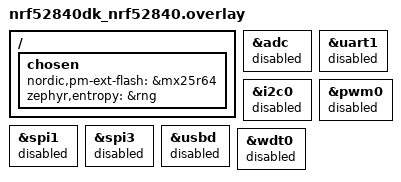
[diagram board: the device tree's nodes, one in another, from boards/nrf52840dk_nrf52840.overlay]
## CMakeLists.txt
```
#
# Copyright (c) 2021 Nordic Semiconductor ASA
#
# SPDX-License-Identifier: LicenseRef-Nordic-5-Clause
#

cmake_minimum_required(VERSION 3.20.0)

find_package(Zephyr HINTS $ENV{ZEPHYR_BASE})

project(matter-template)

# Enable GNU STD support.
include(${ZEPHYR_CONNECTEDHOMEIP_MODULE_DIR}/config/nrfconnect/app/enable-gnu-std.cmake)

# NORDIC SDK APP START

# Include all source files that are located in the Matter common directory.
include(${ZEPHYR_NRF_MODULE_DIR}/samples/matter/common/cmake/source_common.cmake)

# Include Data Model utils
include(${ZEPHYR_NRF_MODULE_DIR}/samples/matter/common/cmake/data_model.cmake)

include(${ZEPHYR_NRF_MODULE_DIR}/samples/matter/common/cmake/zap_helpers.cmake)
ncs_get_zap_parent_dir(ZAP_PARENT_DIR)

target_include_directories(app PRIVATE
    src
    ${ZAP_PARENT_DIR}
)

target_sources(app PRIVATE
    src/app_task.cpp
    src/main.cpp
)

ncs_configure_data_model()
# NORDIC SDK APP END
```

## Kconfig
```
#
# Copyright (c) 2022 Nordic Semiconductor
#
# SPDX-License-Identifier: LicenseRef-Nordic-5-Clause
#
mainmenu "Matter nRF Connect Template Example Application"

# Sample configuration used for Thread networking
if OPENTHREAD

choice OPENTHREAD_NORDIC_LIBRARY_CONFIGURATION
	default OPENTHREAD_NORDIC_LIBRARY_MTD
endchoice

choice OPENTHREAD_DEVICE_TYPE
	default OPENTHREAD_MTD
endchoice

# SED with 0 dBm Thread TX output power for nRF54L15 tag
if BOARD_NRF54L15TAG

config CHIP_ENABLE_ICD_SUPPORT
	default y

config OPENTHREAD_DEFAULT_TX_POWER
	default 0

endif

endif # OPENTHREAD

config CHIP_WIFI
	default y if SHIELD_NRF7002EB2

source "$(ZEPHYR_CONNECTEDHOMEIP_MODULE_DIR)/config/nrfconnect/chip-module/Kconfig.features"
source "$(ZEPHYR_CONNECTEDHOMEIP_MODULE_DIR)/config/nrfconnect/chip-module/Kconfig.defaults"
source "$(ZEPHYR_NRF_MODULE_DIR)/samples/matter/common/src/Kconfig"
source "Kconfig.zephyr"
```

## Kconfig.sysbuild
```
#
# Copyright (c) 2023 Nordic Semiconductor ASA
#
# SPDX-License-Identifier: LicenseRef-Nordic-5-Clause
#

#### Radio core selection
config NRF_DEFAULT_IPC_RADIO
	default y

# Enable IEEE802.15.4 serialization to network core
# This config automatically pulls in the `overlay-802154.conf` in the ipc_radio image
config NETCORE_IPC_RADIO_IEEE802154
	default y if SOC_SERIES_NRF53 && !WIFI_NRF70

# Enable Bluetooth serialization to network core
# This config automatically pulls in the `overlay-bt_hci_ipc.conf` in the ipc_radio image
config NETCORE_IPC_RADIO_BT_HCI_IPC
	default y if SOC_SERIES_NRF53

#### Bootloader
choice BOOTLOADER
	default BOOTLOADER_MCUBOOT if !BOARD_NRF21540DK
endchoice

# The nRF54LC10 DK keeps MCUboot but uses a single application slot:
# it has no external flash and its RRAM cannot hold two Matter-sized slots.
# DFU can be added by introducing external flash.
config MATTER_OTA
	default n if BOARD_NRF54LC10DK

if BOOTLOADER_MCUBOOT

#### DFU multi-image support
config DFU_MULTI_IMAGE_PACKAGE_BUILD
	default y

config DFU_MULTI_IMAGE_PACKAGE_APP
	default y

#### DFU network core configuration
if SOC_SERIES_NRF53

choice MCUBOOT_MODE
	default MCUBOOT_MODE_OVERWRITE_ONLY
endchoice

choice BOOT_SIGNATURE_TYPE
	default BOOT_SIGNATURE_TYPE_RSA
endchoice

config SECURE_BOOT_NETCORE
	default y

config NETCORE_APP_UPDATE
	default y

config MCUBOOT_NRF53_MULTI_IMAGE_UPDATE
	default y if NETCORE_APP_UPDATE

config DFU_MULTI_IMAGE_PACKAGE_NET
	default y

endif # SOC_SERIES_NRF53

endif # BOOTLOADER_MCUBOOT

#### Enable generating factory data
config MATTER_FACTORY_DATA_GENERATE
	default y if !BOARD_NRF21540DK

# Internal flash only for nRF54L15 tag with compression
if BOARD_NRF54L15TAG

choice MCUBOOT_MODE
	default MCUBOOT_MODE_OVERWRITE_ONLY
endchoice

config MCUBOOT_COMPRESSED_IMAGE_SUPPORT
	default y

endif

# Disable Secondary slot for nRF54LC10 DK since it lacks memory to support it.
if BOARD_NRF54LC10DK

choice MCUBOOT_MODE
	default MCUBOOT_MODE_SINGLE_APP
endchoice

endif

# Partition Manager backwards compatibility
if PARTITION_MANAGER

if SOC_NRF54L10

config PM_MCUBOOT_PAD
	default 0x1000

endif # SOC_NRF54L10

if BOARD_NRF54L15TAG

config PM_OVERRIDE_EXTERNAL_DRIVER_CHECK
	default y

config PM_EXTERNAL_FLASH_MCUBOOT_SECONDARY
	default y

endif # BOARD_NRF54L15TAG

if BOARD_NRF54L15DK || BOARD_NRF54LM20DK

# Disable checking the external drivers for nRF54L15 and nRF54LM20 DKs.
config PM_OVERRIDE_EXTERNAL_DRIVER_CHECK
	default y

endif # BOARD_NRF54L15DK || BOARD_NRF54LM20DK

if BOOTLOADER_MCUBOOT

config PM_EXTERNAL_FLASH_MCUBOOT_SECONDARY
	default y

endif # BOOTLOADER_MCUBOOT

endif # PARTITION_MANAGER

source "share/sysbuild/Kconfig"
```

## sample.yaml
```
sample:
  description: Matter Template sample
  name: Matter Template
common:
  tags:
    - sysbuild
    - ci_samples_matter
tests:
  sample.matter.template.debug:
    sysbuild: true
    build_only: true
    extra_args:
      - CONFIG_NCS_SAMPLE_MATTER_OPERATIONAL_KEYS_MIGRATION_TO_ITS=y
    integration_platforms:
      - nrf52840dk/nrf52840
      - nrf5340dk/nrf5340/cpuapp
      - nrf54l15dk/nrf54l15/cpuapp
      - nrf54l15dk/nrf54l10/cpuapp
      - nrf54l15tag/nrf54l15/cpuapp
      - nrf54lm20dk/nrf54lm20b/cpuapp
      - nrf54lm20dk/nrf54lm20a/cpuapp
      - nrf54lc10dk/nrf54lc10a/cpuapp
    platform_allow:
      - nrf52840dk/nrf52840
      - nrf5340dk/nrf5340/cpuapp
      - nrf54l15dk/nrf54l15/cpuapp
      - nrf54l15dk/nrf54l10/cpuapp
      - nrf54l15tag/nrf54l15/cpuapp
      - nrf54lm20dk/nrf54lm20b/cpuapp
      - nrf54lm20dk/nrf54lm20a/cpuapp
      - nrf54lc10dk/nrf54lc10a/cpuapp
  sample.matter.template.nrf7002eb2.debug:
    sysbuild: true
    build_only: true
    extra_args:
      - template_SHIELD=nrf7002eb2
      - SB_CONFIG_WIFI_NRF70=y
    integration_platforms:
      - nrf54lm20dk/nrf54lm20b/cpuapp
      - nrf54lm20dk/nrf54lm20a/cpuapp
    platform_allow:
      - nrf54lm20dk/nrf54lm20b/cpuapp
      - nrf54lm20dk/nrf54lm20a/cpuapp
  sample.matter.template.release:
    sysbuild: true
    build_only: true
    extra_args:
      - FILE_SUFFIX=release
      - CONFIG_NCS_SAMPLE_MATTER_OPERATIONAL_KEYS_MIGRATION_TO_ITS=y
    integration_platforms:
      - nrf52840dk/nrf52840
      - nrf5340dk/nrf5340/cpuapp
      - nrf54l15dk/nrf54l15/cpuapp
      - nrf54l15dk/nrf54l10/cpuapp
      - nrf54l15tag/nrf54l15/cpuapp
      - nrf54lm20dk/nrf54lm20b/cpuapp
      - nrf54lm20dk/nrf54lm20a/cpuapp
      - nrf54lc10dk/nrf54lc10a/cpuapp
    platform_allow:
      - nrf52840dk/nrf52840
      - nrf5340dk/nrf5340/cpuapp
      - nrf54l15dk/nrf54l15/cpuapp
      - nrf54l15dk/nrf54l10/cpuapp
      - nrf54l15tag/nrf54l15/cpuapp
      - nrf54lm20dk/nrf54lm20b/cpuapp
      - nrf54lm20dk/nrf54lm20a/cpuapp
      - nrf54lc10dk/nrf54lc10a/cpuapp
  sample.matter.template.nrf7002eb2.release:
    sysbuild: true
    build_only: true
    extra_args:
      - FILE_SUFFIX=release
      - template_SHIELD=nrf7002eb2
      - SB_CONFIG_WIFI_NRF70=y
    integration_platforms:
      - nrf54lm20dk/nrf54lm20b/cpuapp
      - nrf54lm20dk/nrf54lm20a/cpuapp
    platform_allow:
      - nrf54lm20dk/nrf54lm20b/cpuapp
      - nrf54lm20dk/nrf54lm20a/cpuapp
  sample.matter.template.smp_dfu:
    sysbuild: true
    build_only: true
    extra_args:
      - CONFIG_CHIP_DFU_OVER_BT_SMP=y
      - CONFIG_NCS_SAMPLE_MATTER_OPERATIONAL_KEYS_MIGRATION_TO_ITS=y
    integration_platforms:
      - nrf54l15dk/nrf54l15/cpuapp
      - nrf54l15dk/nrf54l10/cpuapp
      - nrf54l15tag/nrf54l15/cpuapp
      - nrf54lm20dk/nrf54lm20b/cpuapp
      - nrf54lm20dk/nrf54lm20a/cpuapp
    platform_allow:
      - nrf52840dk/nrf52840
      - nrf5340dk/nrf5340/cpuapp
      - nrf54l15dk/nrf54l15/cpuapp
      - nrf54l15dk/nrf54l10/cpuapp
      - nrf54l15tag/nrf54l15/cpuapp
      - nrf54lm20dk/nrf54lm20b/cpuapp
      - nrf54lm20dk/nrf54lm20a/cpuapp
  sample.matter.template.tfm:
    sysbuild: true
    build_only: true
    extra_args:
      - FILE_SUFFIX=tfm
    integration_platforms:
      - nrf54l15dk/nrf54l15/cpuapp/ns
    platform_allow:
      - nrf54l15dk/nrf54l15/cpuapp/ns
  sample.matter.template.tfm.smp_dfu:
    sysbuild: true
    build_only: true
    extra_args:
      - FILE_SUFFIX=tfm
      - CONFIG_CHIP_DFU_OVER_BT_SMP=y
    integration_platforms:
      - nrf54l15dk/nrf54l15/cpuapp/ns
    platform_allow:
      - nrf54l15dk/nrf54l15/cpuapp/ns
  sample.matter.template.nrf7002eb2.smp_dfu:
    sysbuild: true
    build_only: true
    extra_args:
      - CONFIG_CHIP_DFU_OVER_BT_SMP=y
      - template_SHIELD=nrf7002eb2
      - SB_CONFIG_WIFI_NRF70=y
    integration_platforms:
      - nrf54lm20dk/nrf54lm20b/cpuapp
      - nrf54lm20dk/nrf54lm20a/cpuapp
    platform_allow:
      - nrf54lm20dk/nrf54lm20b/cpuapp
      - nrf54lm20dk/nrf54lm20a/cpuapp
  sample.matter.template.release.internal:
    sysbuild: true
    build_only: true
    extra_args:
      - FILE_SUFFIX=internal
      - template_EXTRA_CONF_FILE=prj_release.conf
    integration_platforms:
      - nrf54l15dk/nrf54l15/cpuapp
      - nrf54lm20dk/nrf54lm20b/cpuapp
      - nrf54lm20dk/nrf54lm20a/cpuapp
    platform_allow:
      - nrf54l15dk/nrf54l15/cpuapp
      - nrf54lm20dk/nrf54lm20b/cpuapp
      - nrf54lm20dk/nrf54lm20a/cpuapp
  sample.matter.template.nrf7002eb2.release.internal:
    sysbuild: true
    build_only: true
    extra_args:
      - FILE_SUFFIX=internal
      - template_EXTRA_CONF_FILE=prj_release.conf
      - template_SHIELD=nrf7002eb2
      - SB_CONFIG_WIFI_NRF70=y
    integration_platforms:
      - nrf54lm20dk/nrf54lm20b/cpuapp
      - nrf54lm20dk/nrf54lm20a/cpuapp
    platform_allow:
      - nrf54lm20dk/nrf54lm20b/cpuapp
      - nrf54lm20dk/nrf54lm20a/cpuapp
  sample.matter.template.release.internal.smp_dfu:
    sysbuild: true
    build_only: true
    extra_args:
      - FILE_SUFFIX=internal
      - CONFIG_CHIP_DFU_OVER_BT_SMP=y
      - template_EXTRA_CONF_FILE=prj_release.conf
    integration_platforms:
      - nrf54l15dk/nrf54l15/cpuapp
      - nrf54lm20dk/nrf54lm20b/cpuapp
      - nrf54lm20dk/nrf54lm20a/cpuapp
    platform_allow:
      - nrf54l15dk/nrf54l15/cpuapp
      - nrf54lm20dk/nrf54lm20b/cpuapp
      - nrf54lm20dk/nrf54lm20a/cpuapp
  sample.matter.template.nrf7002eb2.release.internal.smp_dfu:
    sysbuild: true
    build_only: true
    extra_args:
      - FILE_SUFFIX=internal
      - CONFIG_CHIP_DFU_OVER_BT_SMP=y
      - template_EXTRA_CONF_FILE=prj_release.conf
      - template_SHIELD=nrf7002eb2
      - SB_CONFIG_WIFI_NRF70=y
    integration_platforms:
      - nrf54lm20dk/nrf54lm20b/cpuapp
      - nrf54lm20dk/nrf54lm20a/cpuapp
    platform_allow:
      - nrf54lm20dk/nrf54lm20b/cpuapp
      - nrf54lm20dk/nrf54lm20a/cpuapp
  sample.matter.template.cc3xx_backend:
    sysbuild: true
    build_only: true
    extra_args:
      - CONFIG_PSA_CRYPTO_DRIVER_CC3XX=y
    integration_platforms:
      - nrf52840dk/nrf52840
      - nrf5340dk/nrf5340/cpuapp
    platform_allow:
      - nrf52840dk/nrf52840
      - nrf5340dk/nrf5340/cpuapp
  sample.matter.template.smp_dfu.old_ec:
    sysbuild: true
    build_only: true
    extra_args:
      - CONFIG_CHIP_DFU_OVER_BT_SMP=y
      - SB_CONFIG_BOOT_SIGNATURE_TYPE_RSA=y
      - CONFIG_SETTINGS_ZMS_LEGACY=y
    integration_platforms:
      - nrf54l15dk/nrf54l15/cpuapp
    platform_allow:
      - nrf54l15dk/nrf54l15/cpuapp
  sample.matter.template.certification:
    sysbuild: true
    build_only: true
    extra_args:
      - CONFIG_NCS_SAMPLE_MATTER_CERTIFICATION=y
      - OVERLAY_CONFIG="../common/src/certification/thread_platform/overlay-thread_platform.conf"
      - template_SNIPPET="matter-diagnostic-logs;matter-debug"
    integration_platforms:
      - nrf52840dk/nrf52840
      - nrf5340dk/nrf5340/cpuapp
      - nrf54l15dk/nrf54l15/cpuapp
      - nrf54lm20dk/nrf54lm20b/cpuapp
      - nrf54lm20dk/nrf54lm20a/cpuapp
    platform_allow:
      - nrf52840dk/nrf52840
      - nrf5340dk/nrf5340/cpuapp
      - nrf54l15dk/nrf54l15/cpuapp
      - nrf54lm20dk/nrf54lm20b/cpuapp
      - nrf54lm20dk/nrf54lm20a/cpuapp
```

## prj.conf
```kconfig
#
# Copyright (c) 2021 Nordic Semiconductor ASA
#
# SPDX-License-Identifier: LicenseRef-Nordic-5-Clause
#

# This sample uses Kconfig.defaults to set options common for all
# samples. This file should contain only options specific for this sample
# or overrides of default values.

# Enable CHIP
CONFIG_CHIP=y
CONFIG_CHIP_PROJECT_CONFIG="src/chip_project_config.h"
CONFIG_CHIP_DEVICE_PRODUCT_NAME="Matter Template"

# Configure ZAP file name
CONFIG_NCS_SAMPLE_MATTER_ZAP_FILE_PATH="${APPLICATION_CONFIG_DIR}/src/default_zap/template.zap"

# 32768 == 0x8000 (example Product ID added temporaly,
# but it must be changed with proper PID from the list:
# https://github.com/project-chip/connectedhomeip/blob/482e6fd03196a6de45465a90003947ef4b86e0b1/docs/examples/discussion/PID_allocation_for_example_apps.md)
CONFIG_CHIP_DEVICE_PRODUCT_ID=32768
CONFIG_STD_CPP17=y

# Enable Matter pairing automatically on application start.
CONFIG_CHIP_ENABLE_PAIRING_AUTOSTART=y

# Enable Matter extended announcement and increase duration to 1 hour.
CONFIG_CHIP_BLE_EXT_ADVERTISING=y
CONFIG_CHIP_BLE_ADVERTISING_DURATION=60

# Add support for LEDs and buttons on Nordic development kits
CONFIG_DK_LIBRARY=y

# Bluetooth Low Energy configuration
CONFIG_BT_DEVICE_NAME="MatterTemplate"

# Other settings
CONFIG_THREAD_NAME=y
CONFIG_MPU_STACK_GUARD=y
CONFIG_RESET_ON_FATAL_ERROR=n
CONFIG_CHIP_LIB_SHELL=y
CONFIG_NCS_SAMPLE_MATTER_TEST_SHELL=y

# Disable NFC onboarding
CONFIG_CHIP_NFC_ONBOARDING_PAYLOAD=n

# Reduce application size
CONFIG_USE_SEGGER_RTT=n

# Enable Factory Data feature
CONFIG_CHIP_FACTORY_DATA=y
CONFIG_CHIP_FACTORY_DATA_BUILD=y
```

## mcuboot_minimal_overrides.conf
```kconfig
CONFIG_SYS_CLOCK_EXISTS=y
CONFIG_SPI_NOR=y
CONFIG_GPIO=y
CONFIG_PSA_CORE_LITE=n

# NOTE: This had to be added, since toggling LITE on and off did not set it automatically
CONFIG_PSA_CORE_OBERON=y
```

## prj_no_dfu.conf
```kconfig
#
# Copyright (c) 2021 Nordic Semiconductor ASA
#
# SPDX-License-Identifier: LicenseRef-Nordic-5-Clause
#

# This sample uses Kconfig.defaults to set options common for all
# samples. This file should contain only options specific for this sample
# or overrides of default values.

# Enable CHIP
CONFIG_CHIP=y
CONFIG_CHIP_ENABLE_PAIRING_AUTOSTART=y
CONFIG_CHIP_PROJECT_CONFIG="src/chip_project_config.h"
# 32768 == 0x8000 (example Product ID added temporaly,
# but it must be changed with proper PID from the list:
# https://github.com/project-chip/connectedhomeip/blob/482e6fd03196a6de45465a90003947ef4b86e0b1/docs/examples/discussion/PID_allocation_for_example_apps.md)
CONFIG_CHIP_DEVICE_PRODUCT_ID=32768
CONFIG_STD_CPP17=y

# Add support for LEDs and buttons on Nordic development kits
CONFIG_DK_LIBRARY=y

# Bluetooth Low Energy configuration
CONFIG_BT_DEVICE_NAME="MatterTemplate"

# Other settings
CONFIG_THREAD_NAME=y
CONFIG_MPU_STACK_GUARD=y
CONFIG_RESET_ON_FATAL_ERROR=n
CONFIG_CHIP_LIB_SHELL=y

# Disable NFC commissioning
CONFIG_CHIP_NFC_COMMISSIONING=n

# Disable Matter OTA DFU
CONFIG_CHIP_OTA_REQUESTOR=n

# Disable QSPI NOR
CONFIG_CHIP_QSPI_NOR=n

# Reduce application size
CONFIG_USE_SEGGER_RTT=n
```

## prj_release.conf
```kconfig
#
# Copyright (c) 2021 Nordic Semiconductor ASA
#
# SPDX-License-Identifier: LicenseRef-Nordic-5-Clause
#

# This sample uses Kconfig.defaults to set options common for all
# samples. This file should contain only options specific for this sample
# or overrides of default values.

# Enable CHIP
CONFIG_CHIP=y
CONFIG_CHIP_PROJECT_CONFIG="src/chip_project_config.h"
CONFIG_CHIP_DEVICE_PRODUCT_NAME="Matter Template"

# Configure ZAP file name
CONFIG_NCS_SAMPLE_MATTER_ZAP_FILE_PATH="${APPLICATION_CONFIG_DIR}/src/default_zap/template.zap"

# 32768 == 0x8000 (example Product ID added temporaly,
# but it must be changed with proper PID from the list:
# https://github.com/project-chip/connectedhomeip/blob/482e6fd03196a6de45465a90003947ef4b86e0b1/docs/examples/discussion/PID_allocation_for_example_apps.md)
CONFIG_CHIP_DEVICE_PRODUCT_ID=32768
CONFIG_STD_CPP17=y

# Enable Matter pairing automatically on application start.
CONFIG_CHIP_ENABLE_PAIRING_AUTOSTART=y

# Enable Matter extended announcement and increase duration to 1 hour.
CONFIG_CHIP_BLE_EXT_ADVERTISING=y
CONFIG_CHIP_BLE_ADVERTISING_DURATION=60

# Add support for LEDs and buttons on Nordic development kits
CONFIG_DK_LIBRARY=y

# Bluetooth Low Energy configuration
CONFIG_BT_DEVICE_NAME="MatterTemplate"

# Enable system reset on fatal error
CONFIG_RESET_ON_FATAL_ERROR=y

# Disable all debug features
CONFIG_USE_SEGGER_RTT=n
CONFIG_SHELL=n
CONFIG_OPENTHREAD_SHELL=n
CONFIG_CHIP_LIB_SHELL=n
CONFIG_CONSOLE=n
CONFIG_UART_CONSOLE=n
CONFIG_SERIAL=n
CONFIG_LOG=n
CONFIG_LOG_MODE_MINIMAL=n
CONFIG_ASSERT_VERBOSE=n
CONFIG_ASSERT_NO_FILE_INFO=y
CONFIG_PRINTK=n
CONFIG_PRINTK_SYNC=n
CONFIG_THREAD_NAME=n
CONFIG_BOOT_BANNER=n

# Disable NFC onboarding
CONFIG_CHIP_NFC_ONBOARDING_PAYLOAD=n

# Enable Factory Data feature
CONFIG_CHIP_FACTORY_DATA=y
CONFIG_CHIP_FACTORY_DATA_BUILD=y

# Enable Watchdog
CONFIG_NCS_SAMPLE_MATTER_WATCHDOG=y

# Enable LTO to decrease the flash usage.
CONFIG_LTO=y
CONFIG_ISR_TABLES_LOCAL_DECLARATION=y
```

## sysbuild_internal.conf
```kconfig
#
# Copyright (c) 2024 Nordic Semiconductor
#
# SPDX-License-Identifier: LicenseRef-Nordic-5-Clause
#

SB_CONFIG_MATTER=y
SB_CONFIG_PM_OVERRIDE_EXTERNAL_DRIVER_CHECK=n
SB_CONFIG_PM_EXTERNAL_FLASH_MCUBOOT_SECONDARY=n

# Enable the DFU image compression.
SB_CONFIG_MCUBOOT_MODE_OVERWRITE_ONLY=y
SB_CONFIG_MCUBOOT_COMPRESSED_IMAGE_SUPPORT=y
```

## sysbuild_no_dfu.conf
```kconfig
#
# Copyright (c) 2023 Nordic Semiconductor ASA
#
# SPDX-License-Identifier: LicenseRef-Nordic-5-Clause
#

SB_CONFIG_BOOTLOADER_MCUBOOT=n
SB_CONFIG_BOOTLOADER_NONE=y
```

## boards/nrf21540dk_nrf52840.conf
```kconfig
#
# Copyright (c) 2022 Nordic Semiconductor ASA
#
# SPDX-License-Identifier: LicenseRef-Nordic-5-Clause
#

# This sample uses Kconfig.defaults to set options common for all
# samples. This file should contain only options specific for this sample
# or overrides of default values.

# Other settings
CONFIG_THREAD_NAME=y
CONFIG_MPU_STACK_GUARD=y
CONFIG_RESET_ON_FATAL_ERROR=n
CONFIG_CHIP_LIB_SHELL=y

# Disable Matter OTA DFU
CONFIG_CHIP_OTA_REQUESTOR=n

# Disable QSPI NOR
CONFIG_CHIP_QSPI_NOR=n

# Disable Factory data feature since the board doesn't have external flash memory.
CONFIG_CHIP_FACTORY_DATA=n
CONFIG_CHIP_FACTORY_DATA_BUILD=n
```

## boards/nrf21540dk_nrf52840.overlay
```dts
/* Copyright (c) 2021 Nordic Semiconductor ASA
 *
 * SPDX-License-Identifier: LicenseRef-Nordic-5-Clause
 */

/ {
	/*
	* In some default configurations within the nRF Connect SDK,
	* e.g. on nRF52840, the chosen zephyr,entropy node is &cryptocell.
	* This devicetree overlay ensures that default is overridden wherever it
	* is set, as this application uses the RNG node for entropy exclusively.
	*/
	chosen {
		zephyr,entropy = &rng;
	};
};

&wdt0 {
	status = "disabled";
};
```

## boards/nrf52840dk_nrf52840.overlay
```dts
/* Copyright (c) 2021 Nordic Semiconductor ASA
 *
 * SPDX-License-Identifier: LicenseRef-Nordic-5-Clause
 */

/ {
	chosen {
		nordic,pm-ext-flash = &mx25r64;
	};
};


/ {
	/*
	* In some default configurations within the nRF Connect SDK,
	* e.g. on nRF52840, the chosen zephyr,entropy node is &cryptocell.
	* This devicetree overlay ensures that default is overridden wherever it
	* is set, as this application uses the RNG node for entropy exclusively.
	*/
	chosen {
		zephyr,entropy = &rng;
	};
};

/* Disable unused peripherals to reduce power consumption */
&adc {
	status = "disabled";
};
&uart1 {
	status = "disabled";
};
&i2c0 {
	status = "disabled";
};
&pwm0 {
	status = "disabled";
};
&spi1 {
	status = "disabled";
};
&spi3 {
	status = "disabled";
};
&usbd {
	status = "disabled";
};
&wdt0 {
	status = "disabled";
};
```

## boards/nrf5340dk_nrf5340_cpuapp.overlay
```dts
/*
 * Copyright (c) 2021 Nordic Semiconductor ASA
 *
 * SPDX-License-Identifier: LicenseRef-Nordic-5-Clause
 */

#include <samples/matter/nrf5340_cpuapp_partitions.dtsi>
#include <zephyr/dt-bindings/ipc_service/static_vrings.h>

/* Set IPC thread priority to the highest value to not collide with other threads. */
&ipc0 {
	zephyr,priority = <0 PRIO_COOP>;
};

/ {
	chosen {
		nordic,pm-ext-flash = &mx25r64;
	};
};

&mx25r64 {
	status = "okay";
};

/* Disable unused peripherals to reduce power consumption */
&adc {
	status = "disabled";
};

&i2c1 {
	status = "disabled";
};

&pwm0 {
	status = "disabled";
};

&spi2 {
	status = "disabled";
};

&usbd {
	status = "disabled";
};
```

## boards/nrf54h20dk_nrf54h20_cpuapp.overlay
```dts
/*
 * Copyright (c) 2024 Nordic Semiconductor ASA
 *
 * SPDX-License-Identifier: LicenseRef-Nordic-5-Clause
 */

// Base path of the following includes points to the nrf/include directory.
#include <../samples/matter/common/dts/nrf54h20/nrf54h20_cpuapp_peripherals.dtsi>
#include <../samples/matter/common/dts/nrf54h20/nrf54h20_cpuapp_memory_map.dtsi>
#include <../samples/matter/common/dts/nrf54h20/nrf54h20_ram_allocation.dtsi>
```

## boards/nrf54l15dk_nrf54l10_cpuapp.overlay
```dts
/*
 * Copyright (c) 2024 Nordic Semiconductor ASA
 *
 * SPDX-License-Identifier: LicenseRef-Nordic-5-Clause
 */

#include <samples/matter/nrf54l10_cpuapp_partitions.dtsi>

/ {
	aliases {
		/* Use watchdog wdt31 as the application watchdog */
		watchdog0 = &wdt31;
	};

	chosen {
		nordic,pm-ext-flash = &mx25r64;
	};
};

&mx25r64 {
	status = "okay";
};

&wdt31 {
	status = "okay";
};
```

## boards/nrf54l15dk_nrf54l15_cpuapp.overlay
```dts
/*
 * Copyright (c) 2025 Nordic Semiconductor ASA
 *
 * SPDX-License-Identifier: LicenseRef-Nordic-5-Clause
 */

#include <samples/matter/nrf54l15dk_nrf54l15_cpuapp_partitions.dtsi>

/ {
	aliases {
		/* Use watchdog wdt31 as the application watchdog */
		watchdog0 = &wdt31;
	};
};

/* TODO: re-enable HWFC once it's fixed */
&uart20 {
	/delete-property/ hw-flow-control;
};

&wdt31 {
	status = "okay";
};
```

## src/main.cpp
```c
/*
 * Copyright (c) 2021 Nordic Semiconductor ASA
 *
 * SPDX-License-Identifier: LicenseRef-Nordic-5-Clause
 */

#include "app_task.h"

#include <zephyr/logging/log.h>

LOG_MODULE_REGISTER(app, CONFIG_MATTER_LOG_LEVEL);

int main()
{
	CHIP_ERROR err = AppTask::Instance().StartApp();

	LOG_ERR("Exited with code %" CHIP_ERROR_FORMAT, err.Format());
	return err == CHIP_NO_ERROR ? EXIT_SUCCESS : EXIT_FAILURE;
}
```

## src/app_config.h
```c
/*
 * Copyright (c) 2022 Nordic Semiconductor ASA
 *
 * SPDX-License-Identifier: LicenseRef-Nordic-5-Clause
 */

#pragma once

/* ---- Template App Config ---- */

#include "board_util.h"

#define FUNCTION_BUTTON DK_BTN1
#define FUNCTION_BUTTON_MASK DK_BTN1_MSK

#define SYSTEM_STATE_LED DK_LED1
#define FACTORY_RESET_SIGNAL_LED DK_LED2

#if NUMBER_OF_LEDS == 4
#define FACTORY_RESET_SIGNAL_LED1 DK_LED3
#define FACTORY_RESET_SIGNAL_LED2 DK_LED4
#endif
```

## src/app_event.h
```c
/*
 * Copyright (c) 2021 Nordic Semiconductor ASA
 *
 * SPDX-License-Identifier: LicenseRef-Nordic-5-Clause
 */

#pragma once

#include <cstdint>

#include "event_types.h"

class LEDWidget;

enum class AppEventType : uint8_t { None = 0, Button, ButtonPushed, ButtonReleased, Timer, UpdateLedState };

enum class FunctionEvent : uint8_t { NoneSelected = 0, FactoryReset };

struct AppEvent {
	union {
		struct {
			uint8_t PinNo;
			uint8_t Action;
		} ButtonEvent;
		struct {
			void *Context;
		} TimerEvent;
		struct {
			LEDWidget *LedWidget;
		} UpdateLedStateEvent;
	};

	AppEventType Type{ AppEventType::None };
	EventHandler Handler;
};
```

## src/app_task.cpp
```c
/*
 * Copyright (c) 2021 Nordic Semiconductor ASA
 *
 * SPDX-License-Identifier: LicenseRef-Nordic-5-Clause
 */

#include "app_task.h"

#include "app/matter_init.h"
#include "app/task_executor.h"
#include "board/board.h"
#include "lib/core/CHIPError.h"
#include "lib/support/CodeUtils.h"

#include <setup_payload/OnboardingCodesUtil.h>

#include <zephyr/logging/log.h>

LOG_MODULE_DECLARE(app, CONFIG_CHIP_APP_LOG_LEVEL);

using namespace ::chip;
using namespace ::chip::app;
using namespace ::chip::DeviceLayer;

CHIP_ERROR AppTask::Init()
{
	/* Initialize Matter stack */
	ReturnErrorOnFailure(Nrf::Matter::PrepareServer());

	if (!Nrf::GetBoard().Init()) {
		LOG_ERR("User interface initialization failed.");
		return CHIP_ERROR_INCORRECT_STATE;
	}

	/* Register Matter event handler that controls the connectivity status LED based on the captured Matter network
	 * state. */
	ReturnErrorOnFailure(Nrf::Matter::RegisterEventHandler(Nrf::Board::DefaultMatterEventHandler, 0));

	return Nrf::Matter::StartServer();
}

CHIP_ERROR AppTask::StartApp()
{
	ReturnErrorOnFailure(Init());

	while (true) {
		Nrf::DispatchNextTask();
	}

	return CHIP_NO_ERROR;
}
```

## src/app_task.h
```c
/*
 * Copyright (c) 2021 Nordic Semiconductor ASA
 *
 * SPDX-License-Identifier: LicenseRef-Nordic-5-Clause
 */

#pragma once

#include <platform/CHIPDeviceLayer.h>

struct k_timer;

class AppTask {
public:
	static AppTask &Instance()
	{
		static AppTask sAppTask;
		return sAppTask;
	};

	CHIP_ERROR StartApp();

private:
	CHIP_ERROR Init();
};
```

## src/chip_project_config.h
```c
/*
 * Copyright (c) 2021 Nordic Semiconductor ASA
 *
 * SPDX-License-Identifier: LicenseRef-Nordic-5-Clause
 */

/**
 *    @file
 *          Example project configuration file for CHIP.
 *
 *          This is a place to put application or project-specific overrides
 *          to the default configuration values for general CHIP features.
 *
 */

#pragma once

/**
 * CHIP_DEVICE_CONFIG_DEVICE_PRODUCT_ID
 *
 * 0x4E54: nrfconnect template
 */
#define CHIP_DEVICE_CONFIG_DEVICE_PRODUCT_ID 0x4E54

/* Use a default pairing code if one hasn't been provisioned in flash. */
#define CHIP_DEVICE_CONFIG_USE_TEST_SETUP_PIN_CODE 20202021
#define CHIP_DEVICE_CONFIG_USE_TEST_SETUP_DISCRIMINATOR 0xF00
```
